AUTOSAR XML (schema 4-0-3)
standard types defined: Boolean, UInt16, UInt32, UInt8
package /AUTOSAR_Platform/DataConstrs
  range DC_Boolean: raw 0..1
  range DC_UInt16: raw 0..65535
  range DC_UInt8: raw 0..255
package /PATAC/MSM/ComponentTypes
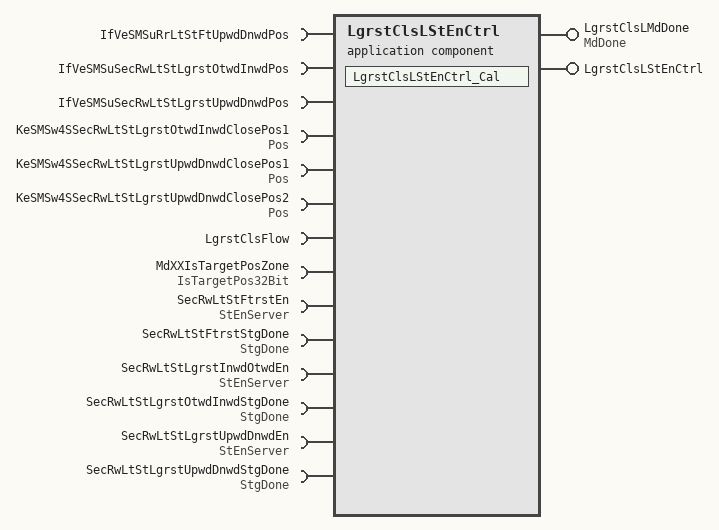
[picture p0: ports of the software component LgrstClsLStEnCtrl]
  application sw component type LgrstClsLStEnCtrl
    provide port LgrstClsLMdDone: nonqueued-sender-com-spec{data-element=MdDone/Val, init-value=0}, provided-interface=MdDone
    provide port LgrstClsLStEnCtrl: server-com-spec{operation=LgrstClsLStEnCtrl/Cal, queue-length=1}, provided-interface=LgrstClsLStEnCtrl
    14 x require port:
      IfVeSMSuRrLtStFtUpwdDnwdPos: nonqueued-receiver-com-spec{data-element=IfVeSMSuRrLtStFtUpwdDnwdPos/Val, filter=data-filter-type=ALWAYS, init-value=0}, required-interface=IfVeSMSuRrLtStFtUpwdDnwdPos
      IfVeSMSuSecRwLtStLgrstOtwdInwdPos: nonqueued-receiver-com-spec{data-element=IfVeSMSuSecRwLtStLgrstOtwdInwdPos/Val, filter=data-filter-type=ALWAYS, init-value=0}, required-interface=IfVeSMSuSecRwLtStLgrstOtwdInwdPos
      IfVeSMSuSecRwLtStLgrstUpwdDnwdPos: nonqueued-receiver-com-spec{data-element=IfVeSMSuSecRwLtStLgrstUpwdDnwdPos/Val, filter=data-filter-type=ALWAYS, init-value=0}, required-interface=IfVeSMSuSecRwLtStLgrstUpwdDnwdPos
      KeSMSw4SSecRwLtStLgrstOtwdInwdClosePos1: parameter-require-com-spec{init-value=0, parameter=Val}, required-interface=Pos
      KeSMSw4SSecRwLtStLgrstUpwdDnwdClosePos1: parameter-require-com-spec{init-value=0, parameter=Val}, required-interface=Pos
      KeSMSw4SSecRwLtStLgrstUpwdDnwdClosePos2: parameter-require-com-spec{init-value=0, parameter=Val}, required-interface=Pos
      LgrstClsFlow: client-com-spec=LgrstClsFlow/Cal, required-interface=LgrstClsFlow
      MdXXIsTargetPosZone: nonqueued-receiver-com-spec{data-element=IsTargetPos32Bit/Val, filter=data-filter-type=ALWAYS, init-value=0}, required-interface=IsTargetPos32Bit
      SecRwLtStFtrstEn: required-com-specs=[Clear, Get, Set], required-interface=StEnServer
      SecRwLtStFtrstStgDone: nonqueued-receiver-com-spec{data-element=StgDone/Val, filter=data-filter-type=ALWAYS, init-value=0}, required-interface=StgDone
      SecRwLtStLgrstInwdOtwdEn: required-com-specs=[Clear, Get, Set], required-interface=StEnServer
      SecRwLtStLgrstOtwdInwdStgDone: nonqueued-receiver-com-spec{data-element=StgDone/Val, filter=data-filter-type=ALWAYS, init-value=0}, required-interface=StgDone
      SecRwLtStLgrstUpwdDnwdEn: required-com-specs=[Clear, Get, Set], required-interface=StEnServer
      SecRwLtStLgrstUpwdDnwdStgDone: nonqueued-receiver-com-spec{data-element=StgDone/Val, filter=data-filter-type=ALWAYS, init-value=0}, required-interface=StgDone
    behavior LgrstClsLStEnCtrl_InternalBehavior
      operation invoked event OIT_LgrstClsLStEnCtrl_Cal_LgrstClsLStEnCtrl_Cal: start-on-event=LgrstClsLStEnCtrl_Cal, operation=LgrstClsLStEnCtrl.Cal
      runnable LgrstClsLStEnCtrl_Cal
        data-receive-point-by-arguments:
          7 x access:
            REC_IfVeSMSuRrLtStFtUpwdDnwdPos_Val: accessed-variable=IfVeSMSuRrLtStFtUpwdDnwdPos.Val
            REC_IfVeSMSuSecRwLtStLgrstOtwdInwdPos_Val: accessed-variable=IfVeSMSuSecRwLtStLgrstOtwdInwdPos.Val
            REC_IfVeSMSuSecRwLtStLgrstUpwdDnwdPos_Val: accessed-variable=IfVeSMSuSecRwLtStLgrstUpwdDnwdPos.Val
            REC_MdXXIsTargetPosZone_Val: accessed-variable=MdXXIsTargetPosZone.Val
            REC_SecRwLtStFtrstStgDone_Val: accessed-variable=SecRwLtStFtrstStgDone.Val
            REC_SecRwLtStLgrstOtwdInwdStgDone_Val: accessed-variable=SecRwLtStLgrstOtwdInwdStgDone.Val
            REC_SecRwLtStLgrstUpwdDnwdStgDone_Val: accessed-variable=SecRwLtStLgrstUpwdDnwdStgDone.Val
        data-send-points:
          access SEND_LgrstClsLMdDone_Val: accessed-variable=LgrstClsLMdDone.Val
        parameter access PA_KeSMSw4SSecRwLtStLgrstOtwdInwdClosePos1_Val: accessed-parameter=KeSMSw4SSecRwLtStLgrstOtwdInwdClosePos1.Val
        parameter access PA_KeSMSw4SSecRwLtStLgrstUpwdDnwdClosePos1_Val: accessed-parameter=KeSMSw4SSecRwLtStLgrstUpwdDnwdClosePos1.Val
        parameter access PA_KeSMSw4SSecRwLtStLgrstUpwdDnwdClosePos2_Val: accessed-parameter=KeSMSw4SSecRwLtStLgrstUpwdDnwdClosePos2.Val
        7 x sync call, all with timeout=0:
          SC_LgrstClsFlow_Cal: operation=LgrstClsFlow.Cal
          SC_SecRwLtStFtrstEn_Clear: operation=SecRwLtStFtrstEn.Clear
          SC_SecRwLtStFtrstEn_Set: operation=SecRwLtStFtrstEn.Set
          SC_SecRwLtStLgrstInwdOtwdEn_Clear: operation=SecRwLtStLgrstInwdOtwdEn.Clear
          SC_SecRwLtStLgrstInwdOtwdEn_Set: operation=SecRwLtStLgrstInwdOtwdEn.Set
          SC_SecRwLtStLgrstUpwdDnwdEn_Clear: operation=SecRwLtStLgrstUpwdDnwdEn.Clear
          SC_SecRwLtStLgrstUpwdDnwdEn_Set: operation=SecRwLtStLgrstUpwdDnwdEn.Set
  swc implementation LgrstClsLStEnCtrl_Implementation: behavior=LgrstClsLStEnCtrl_InternalBehavior
    code-descriptors:
      code Default: artifact-descriptors=autosar-engineering-object={short-label=Default, category=SWSRC}
package /PATAC/MSM/ModeAdjust/CalPortInterface
  parameter interface Pos
    parameter data prototype Val: sw-calibration-access=READ-WRITE, type=UInt16
package /PATAC/MSM/ModeAdjust/PortInterface
  client server interface LgrstClsFlow
    operation Cal
      13 x arg, all with server-argument-impl-policy=USE-ARGUMENT-TYPE:
        LgrstUpwdDnwdPos: type=UInt16, direction=IN
        LgrstOtwdInwdPos: type=UInt16, direction=IN
        FtUpwdDnwdPos: type=UInt16, direction=IN
        CloseDnwdPos1: type=UInt16, direction=IN
        CloseDnwdPos2: type=UInt16, direction=IN
        CloseOtwdPos1: type=UInt16, direction=IN
        LgrstInwdStgDone: type=Boolean, direction=IN
        LgrstUpwdStgDone: type=Boolean, direction=IN
        FtrstStgDone: type=Boolean, direction=IN
        Failflg: type=Boolean, direction=OUT
        LgrstInwdOtwdEn: type=Boolean, direction=OUT
        LgrstUpwdDnwdEn: type=Boolean, direction=OUT
        FtrstEn: type=Boolean, direction=OUT
  client server interface LgrstClsLStEnCtrl
    operation Cal
  client server interface StEnServer
    operation Clear
      arg data: type=UInt8, direction=IN, server-argument-impl-policy=USE-ARGUMENT-TYPE
    operation Get
      arg data: type=UInt32, direction=OUT, server-argument-impl-policy=USE-ARGUMENT-TYPE
    operation Set
      arg data: type=UInt8, direction=IN, server-argument-impl-policy=USE-ARGUMENT-TYPE
  sender receiver interface IsTargetPos32Bit: invalidation-policy{data-element=IsTargetPos32Bit/Val, handle-invalid=DONT-INVALIDATE}
    data Val: type=UInt32
  sender receiver interface MdDone: invalidation-policy{data-element=MdDone/Val, handle-invalid=DONT-INVALIDATE}
    data Val: type=UInt8
  sender receiver interface StgDone: invalidation-policy{data-element=StgDone/Val, handle-invalid=DONT-INVALIDATE}
    data Val: type=Boolean
package /PATAC/MSM/PortInterfaces
  sender receiver interface IfVeSMSuRrLtStFtUpwdDnwdPos: invalidation-policy{data-element=IfVeSMSuRrLtStFtUpwdDnwdPos/Val, handle-invalid=DONT-INVALIDATE}
    data Val: type=UInt16
  sender receiver interface IfVeSMSuSecRwLtStLgrstOtwdInwdPos: invalidation-policy{data-element=IfVeSMSuSecRwLtStLgrstOtwdInwdPos/Val, handle-invalid=DONT-INVALIDATE}
    data Val: type=UInt16
  sender receiver interface IfVeSMSuSecRwLtStLgrstUpwdDnwdPos: invalidation-policy{data-element=IfVeSMSuSecRwLtStLgrstUpwdDnwdPos/Val, handle-invalid=DONT-INVALIDATE}
    data Val: type=UInt16
